# LPC1102 register map
File version: 3
Registers are 32-bit, read-write, reset 0x0 unless marked. A register's access mark holds for its fields unless they carry their own. Offsets are from the block's base; [hi:lo] are bit positions; {n}, {i} and the like mark numbered series.

## SYSCON — Product name title=UM10429 Chapter title=LPC1102 System configuration Modification date=11/1/2010 Major revision=1 Minor revision=not available
Base 0x40048000
0x00 SYSMEMREMAP reset 0x2 — System memory remap
  [1:0] MAP
    0=Boot Loader Mode. Interrupt vectors are re-mapped to Boot ROM.; 1=User RAM Mode. Interrupt vectors are re-mapped to Static RAM.; 2=User Flash Mode. Interrupt vectors are not re-mapped and reside in Flash.; 3=User Flash Mode. Interrupt vectors are not re-mapped and reside in Flash.
0x04 PRESETCTRL — Peripheral reset control
  [0] SSP0_RST_N — SPI0 reset control
    0=Resets the SPI0 peripheral; 1=SPI0 reset de-asserted
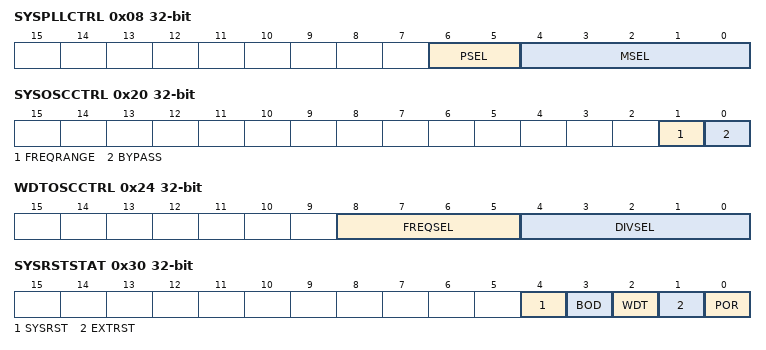
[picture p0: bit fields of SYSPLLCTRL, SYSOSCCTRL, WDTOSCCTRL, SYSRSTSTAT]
0x08 SYSPLLCTRL — System PLL control
  [6:5] PSEL — Post divider ratio P. The division ratio is 2 x P.
    0=P = 1; 1=P = 2; 2=P = 4; 3=P = 8
  [4:0] MSEL — Feedback divider value. The division value M is the programmed MSEL value + 1. 00000: Division ratio M = 1 to 11111: Division ration M = 32
0x0C SYSPLLSTAT ro — System PLL status
  [0] LOCK — PLL lock status
    0=PLL not locked; 1=PLL locked
0x20 SYSOSCCTRL — System oscillator control
  [1] FREQRANGE — Determines frequency range for Low-power oscillator.
    0=1 - 20 MHz frequency range; 1=15 - 25 MHz frequency range
  [0] BYPASS — Bypass system oscillator
    0=Oscillator is not bypassed; 1=Bypass enabled. PLL input (sys_osc_clk) is fed directly from the XTALIN pin.
0x24 WDTOSCCTRL — Watchdog oscillator control
  [8:5] FREQSEL — Select watchdog oscillator analog output frequency (Fclkana).
    1=0.5 MHz; 2=0.8 MHz; 3=1.1 MHz; 4=1.4 MHz; 5=1.6 MHz; 6=1.8 MHz; 7=2.0 MHz; 8=2.2 MHz; 9=2.4 MHz; 10=2.6 MHz; 11=2.7 MHz; 12=2.9 MHz; 13=3.1 MHz; 14=3.2 MHz; 15=3.4 MHz
  [4:0] DIVSEL — Select divider for Fclkana. wdt_osc_clk = Fclkana/ (2 x (1 + DIVSEL)) 00000: 2 x (1 + DIVSEL) = 2 00001: 2 x (1 + DIVSEL) = 4 to 11111: 2 x (1 + DIVSEL) = 64
0x28 IRCCTRL reset 0x80 — IRC control
  [7:0] TRIM — Trim value
0x30 SYSRSTSTAT ro — System reset status register
  [4] SYSRST — Status of the software system reset
    0=no System reset detected; 1=System reset detected
  [3] BOD — Status of the Brown-out detect reset
    0=no BOD reset detected; 1=BOD reset detected
  [2] WDT — Status of the Watchdog reset
    0=no WDT reset detected; 1=WDT reset detected
  [1] EXTRST — RESET pin status
    0=no RESET event detected; 1=RESET detected
  [0] POR — POR reset status
    0=no POR detected; 1=POR detected
0x40 SYSPLLCLKSEL — System PLL clock source select
  [1:0] SEL — System PLL clock source
    0=IRC oscillator; 1=System oscillator
0x44 SYSPLLCLKUEN — System PLL clock source update enable
  [0] ENA — Enable system PLL clock source update
    0=No change; 1=Update clock source
0x70 MAINCLKSEL — Main clock source select
  [1:0] SEL — Clock source for main clock
    0=IRC oscillator; 1=Input clock to system PLL; 2=WDT oscillator; 3=System PLL clock out
0x74 MAINCLKUEN — Main clock source update enable
  [0] ENA — Enable main clock source update
    0=No change; 1=Update clock source
0x78 SYSAHBCLKDIV reset 0x1 — System AHB clock divider
  [7:0] DIV — System AHB clock divider values 0: System clock disabled. 1: Divide by 1. to 255: Divide by 255.
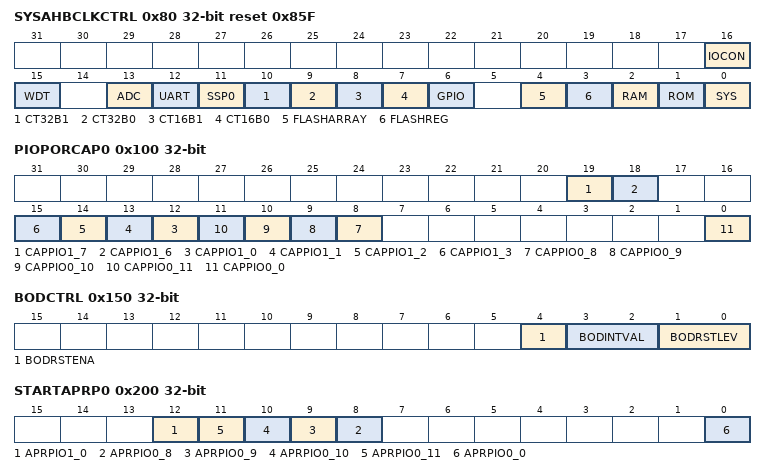
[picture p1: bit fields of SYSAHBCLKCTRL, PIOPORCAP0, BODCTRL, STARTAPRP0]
0x80 SYSAHBCLKCTRL reset 0x85F — System AHB clock control
  [16] IOCON — Enables clock for I/O configuration block.
    0=Disable; 1=Enable
  [15] WDT — Enables clock for WDT.
    0=Disable; 1=Enable
  [13] ADC — Enables clock for ADC.
    0=Disable; 1=Enable
  [12] UART — Enables clock for UART. Note that the UART pins must be configured in the IOCON block before the UART clock can be enabled.
    0=Disable; 1=Enable
  [11] SSP0 — Enables clock for SPI0.
    0=Disable; 1=Enable
  [10] CT32B1 — Enables clock for 32-bit counter/timer 1.
    0=Disable; 1=Enable
  [9] CT32B0 — Enables clock for 32-bit counter/timer 0.
    0=Disable; 1=Enable
  [8] CT16B1 — Enables clock for 16-bit counter/timer 1.
    0=Disable; 1=Enable
  [7] CT16B0 — Enables clock for 16-bit counter/timer 0.
    0=Disable; 1=Enable
  [6] GPIO — Enables clock for GPIO.
    0=Disable; 1=Enable
  [4] FLASHARRAY — Enables clock for flash array access.
    0=Disabled; 1=Enabled
  [3] FLASHREG — Enables clock for flash register interface.
    0=Disabled; 1=Enabled
  [2] RAM — Enables clock for RAM.
    0=Disable; 1=Enable
  [1] ROM — Enables clock for ROM.
    0=Disable; 1=Enable
  [0] SYS — Enables clock for AHB to APB bridge, to the AHB matrix, to the Cortex-M0 FCLK and HCLK, to the SysCon, and to the PMU. This bit is read only.
    1=Enable
0x94 SSP0CLKDIV — SPI0 clock divder
  [7:0] DIV — SPI0_PCLK clock divider values 0: Disable SPI0_PCLK. 1: Divide by 1. to 255: Divide by 255.
0x98 UARTCLKDIV — UART clock divder
  [7:0] DIV — UART_PCLK clock divider values 0: Disable UART_PCLK. 1: Divide by 1. to 255: Divide by 255.
0xD0 WDTCLKSEL — WDT clock source select
  [1:0] SEL — WDT clock source
    0=IRC oscillator; 1=Main clock; 2=Watchdog oscillator
0xD4 WDTCLKUEN — WDT clock source update enable
  [0] ENA — Enable WDT clock source update
    0=No change; 1=Update clock source
0xD8 WDTCLKDIV — WDT clock divider
  [7:0] DIV — WDT clock divider values 0: Disable WDT_PCLK. 1: Divide by 1. to 255: Divide by 255.
0x100 PIOPORCAP0 ro reset not defined — POR captured PIO status 0
  [19] CAPPIO1_7 — Raw reset status input PIO1_7
  [18] CAPPIO1_6 — Raw reset status input PIO1_6
  [n+12] CAPPIO1_{n} (n=0..3) — Raw reset status input PIO1_{n}
  [n] CAPPIO0_{n} (n=8..11) — Raw reset status input PIO0_{n}
  [0] CAPPIO0_0 — Raw reset status input PIO0_0
0x150 BODCTRL — BOD control
  [4] BODRSTENA — BOD reset enable
    0=Disable reset function; 1=Enable reset function
  [3:2] BODINTVAL — BOD interrupt level
    0=Level 0: The interrupt assertion threshold voltage is 1.65 V; the interrupt de-assertion threshold voltage is 1.80 V; 1=Level 1:The interrupt assertion threshold voltage is 2.22 V; the interrupt de-assertion threshold voltage is 2.35 V; 2=Level 2: The interrupt assertion threshold voltage is 2.52 V; the interrupt de-assertion threshold voltage is 2.66 V; 3=Level 3: The interrupt assertion threshold voltage is 2.80 V; the interrupt de-assertion threshold voltage is 2.90 V
  [1:0] BODRSTLEV — BOD reset level
    0=Level 0: The reset assertion threshold voltage is 1.46 V; the reset de-assertion threshold voltage is 1.63 V; 1=Level 1: The reset assertion threshold voltage is 2.06 V; the reset de-assertion threshold voltage is 2.15 V; 2=Level 2: The reset assertion threshold voltage is 2.35 V; the reset de-assertion threshold voltage is 2.43 V; 3=Level 3: The reset assertion threshold voltage is 2.63 V; the reset de-assertion threshold voltage is 2.71 V
0x154 SYSTCKCAL reset 0x4 — System tick counter calibration
  [25:0] CAL — System tick timer calibration value
0x200 STARTAPRP0 reset not defined — Start logic edge control register 0
  [all] fields
    0=Falling edge; 1=Rising edge
  [12] APRPIO1_0 — Edge select for start logic input PIO1_0.
  [n] APRPIO0_{n} (n=8..11) — Edge select for start logic input PIO0_{n}
  [0] APRPIO0_0 — Edge select for start logic input PIO0_0
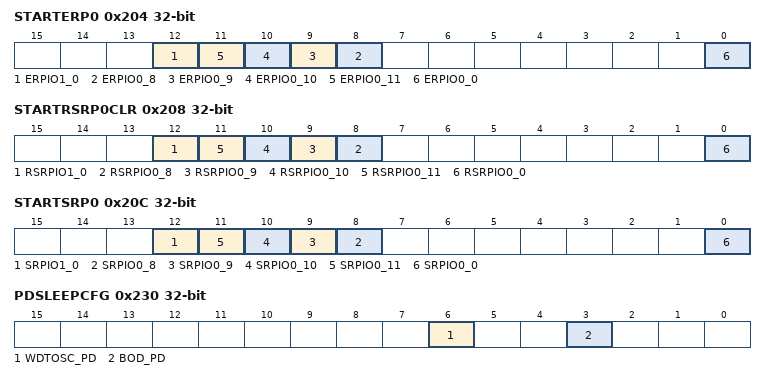
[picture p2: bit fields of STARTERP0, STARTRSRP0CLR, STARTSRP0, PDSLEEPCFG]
0x204 STARTERP0 reset not defined — Start logic signal enable register 0
  [all] fields
    0=Disabled; 1=Enabled
  [12] ERPIO1_0 — Enable start signal for start logic input PIO1_0
  [n] ERPIO0_{n} (n=8..11) — Enable start signal for start logic input PIO0_{n}
  [0] ERPIO0_0 — Enable start signal for start logic input PIO0_0
0x208 STARTRSRP0CLR wo reset not defined — Start logic reset register 0
  [all] fields
    1=Write: reset start signal
  [12] RSRPIO1_0 — Start signal reset for start logic input PIO1_0
  [n] RSRPIO0_{n} (n=8..11) — Start signal reset for start logic input PIO0_{n}
  [0] RSRPIO0_0 — Start signal reset for start logic input PIO0_0
0x20C STARTSRP0 ro reset not defined — Start logic status register 0
  [all] fields
    0=No start signal received; 1=Start signal pending
  [12] SRPIO1_0 — Start signal status for start logic input PIO1_0
  [n] SRPIO0_{n} (n=8..11) — Start signal status for start logic input PIO0_{n}
  [0] SRPIO0_0 — Start signal status for start logic input 0PIO0_0
0x230 PDSLEEPCFG — Power-down states in Deep-sleep mode
  [6] WDTOSC_PD — Watchdog oscillator power control in Deep-sleep mode, see Table 32.
    0=Powered; 1=Powered down
  [3] BOD_PD — BOD power-down control in Deep-sleep mode, see Table 32.
    0=Powered; 1=Powered down
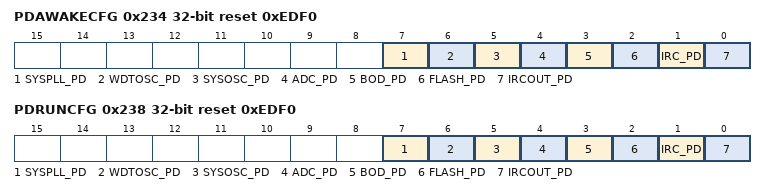
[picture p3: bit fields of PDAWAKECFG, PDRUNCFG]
0x234 PDAWAKECFG reset 0xEDF0 — Power-down states after wake-up from Deep-sleep mode
  [all] fields
    0=Powered; 1=Powered down
  [7] SYSPLL_PD — System PLL wake-up configuration
  [6] WDTOSC_PD — Watchdog oscillator wake-up configuration
  [5] SYSOSC_PD — System oscillator wake-up configuration
  [4] ADC_PD — ADC wake-up configuration
  [3] BOD_PD — BOD wake-up configuration
  [2] FLASH_PD — Flash wake-up configuration
  [1] IRC_PD — IRC oscillator power-down wake-up configuration
  [0] IRCOUT_PD — IRC oscillator output wake-up configuration
0x238 PDRUNCFG reset 0xEDF0 — Power-down configuration register
  [all] fields
    0=Powered; 1=Powered down
  [7] SYSPLL_PD — System PLL power-down
  [6] WDTOSC_PD — Watchdog oscillator power-down
  [5] SYSOSC_PD — System oscillator power-down
  [4] ADC_PD — ADC power-down
  [3] BOD_PD — BOD power-down
  [2] FLASH_PD — Flash power-down
  [1] IRC_PD — IRC oscillator power-down
  [0] IRCOUT_PD — IRC oscillator output power-down
0x3F4 DEVICE_ID ro reset not defined
  [31:0] DEVICEID — Part ID numbers for LPC1102 parts LPC1102 = 0x2500 102B
